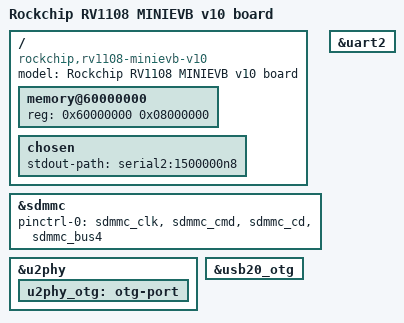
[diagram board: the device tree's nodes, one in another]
// SPDX-License-Identifier: (GPL-2.0+ OR MIT)

/dts-v1/;

#include "rv1108.dtsi"

/ {
	model = "Rockchip RV1108 MINIEVB v10 board";
	compatible = "rockchip,rv1108-minievb-v10", "rockchip,rv1108";

	memory@60000000 {
		device_type = "memory";
		reg = <0x60000000 0x08000000>;
	};

	chosen {
		stdout-path = "serial2:1500000n8";
	};
};

&sdmmc {
	pinctrl-names = "default";
	pinctrl-0 = <&sdmmc_clk &sdmmc_cmd &sdmmc_cd &sdmmc_bus4>;
	status = "okay";
};

&u2phy {
	status = "okay";

	u2phy_otg: otg-port {
		status = "okay";
	};
};

&uart2 {
	status = "okay";
};

&usb20_otg {
	status = "okay";
};
